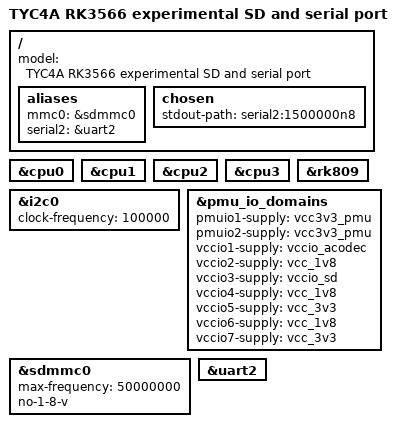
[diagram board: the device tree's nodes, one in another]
// SPDX-License-Identifier: (GPL-2.0+ OR MIT)
// Experimental SD/serial port. Hardware boot remains untested.
#include "rk3566-tyc4a.dts"

/ {
	model = "TYC4A RK3566 experimental SD and serial port";
	aliases {
		mmc0 = &sdmmc0;
		serial2 = &uart2;
	};
	chosen {
		stdout-path = "serial2:1500000n8";
	};
};

// Preserve the bootloader CPU clock until the external CPU regulator is ported.
&cpu0 { /delete-property/ operating-points-v2; };
&cpu1 { /delete-property/ operating-points-v2; };
&cpu2 { /delete-property/ operating-points-v2; };
&cpu3 { /delete-property/ operating-points-v2; };

&i2c0 {
	clock-frequency = <100000>;
	status = "okay";
};

&rk809 {
	status = "okay";
};

// Supply mapping follows the board's Android device tree.
&pmu_io_domains {
	pmuio1-supply = <&vcc3v3_pmu>;
	pmuio2-supply = <&vcc3v3_pmu>;
	vccio1-supply = <&vccio_acodec>;
	vccio2-supply = <&vcc_1v8>;
	vccio3-supply = <&vccio_sd>;
	vccio4-supply = <&vcc_1v8>;
	vccio5-supply = <&vcc_3v3>;
	vccio6-supply = <&vcc_1v8>;
	vccio7-supply = <&vcc_3v3>;
	status = "okay";
};

&sdmmc0 {
	max-frequency = <50000000>;
	no-1-8-v;
	status = "okay";
};

&uart2 {
	status = "okay";
};
